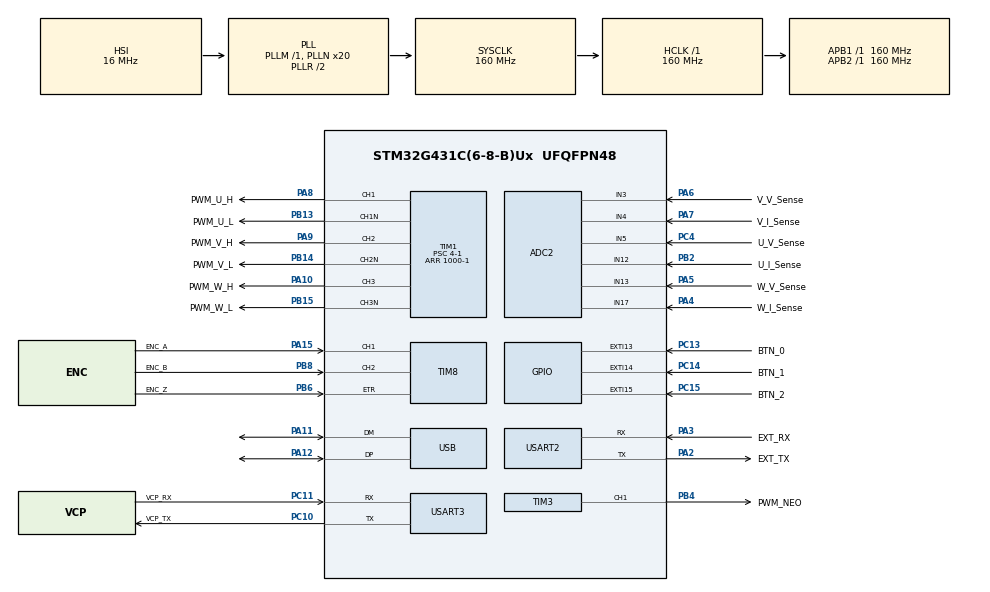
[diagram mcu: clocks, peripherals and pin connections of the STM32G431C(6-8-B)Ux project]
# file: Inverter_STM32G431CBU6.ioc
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ADC2.Channel-0\#ChannelRegularConversion=ADC_CHANNEL_5
ADC2.Channel-1\#ChannelRegularConversion=ADC_CHANNEL_3
ADC2.Channel-2\#ChannelRegularConversion=ADC_CHANNEL_13
ADC2.Channel-3\#ChannelRegularConversion=ADC_CHANNEL_12
ADC2.Channel-4\#ChannelRegularConversion=ADC_CHANNEL_4
ADC2.Channel-5\#ChannelRegularConversion=ADC_CHANNEL_17
ADC2.DMAContinuousRequests=ENABLE
ADC2.ExternalTrigConv=ADC_EXTERNALTRIG_T1_TRGO
ADC2.NbrOfConversion=6
ADC2.NbrOfConversionFlag=1
ADC2.OffsetNumber-0\#ChannelRegularConversion=ADC_OFFSET_NONE
ADC2.OffsetNumber-1\#ChannelRegularConversion=ADC_OFFSET_NONE
ADC2.OffsetNumber-2\#ChannelRegularConversion=ADC_OFFSET_NONE
ADC2.OffsetNumber-3\#ChannelRegularConversion=ADC_OFFSET_NONE
ADC2.OffsetNumber-4\#ChannelRegularConversion=ADC_OFFSET_NONE
ADC2.OffsetNumber-5\#ChannelRegularConversion=ADC_OFFSET_NONE
ADC2.Rank-0\#ChannelRegularConversion=1
ADC2.Rank-1\#ChannelRegularConversion=2
ADC2.Rank-2\#ChannelRegularConversion=3
ADC2.Rank-3\#ChannelRegularConversion=4
ADC2.Rank-4\#ChannelRegularConversion=5
ADC2.Rank-5\#ChannelRegularConversion=6
ADC2.SamplingTime-0\#ChannelRegularConversion=ADC_SAMPLETIME_12CYCLES_5
ADC2.SamplingTime-1\#ChannelRegularConversion=ADC_SAMPLETIME_12CYCLES_5
ADC2.SamplingTime-2\#ChannelRegularConversion=ADC_SAMPLETIME_12CYCLES_5
ADC2.SamplingTime-3\#ChannelRegularConversion=ADC_SAMPLETIME_12CYCLES_5
ADC2.SamplingTime-4\#ChannelRegularConversion=ADC_SAMPLETIME_12CYCLES_5
ADC2.SamplingTime-5\#ChannelRegularConversion=ADC_SAMPLETIME_12CYCLES_5
Dma.ADC2.1.Direction=DMA_PERIPH_TO_MEMORY
Dma.ADC2.1.EventEnable=DISABLE
Dma.ADC2.1.Instance=DMA1_Channel2
Dma.ADC2.1.MemDataAlignment=DMA_MDATAALIGN_HALFWORD
Dma.ADC2.1.MemInc=DMA_MINC_ENABLE
Dma.ADC2.1.Mode=DMA_CIRCULAR
Dma.ADC2.1.PeriphDataAlignment=DMA_PDATAALIGN_HALFWORD
Dma.ADC2.1.PeriphInc=DMA_PINC_DISABLE
Dma.ADC2.1.Polarity=HAL_DMAMUX_REQ_GEN_RISING
Dma.ADC2.1.Priority=DMA_PRIORITY_LOW
Dma.ADC2.1.RequestNumber=1
Dma.ADC2.1.SignalID=NONE
Dma.ADC2.1.SyncEnable=DISABLE
Dma.ADC2.1.SyncPolarity=HAL_DMAMUX_SYNC_NO_EVENT
Dma.ADC2.1.SyncRequestNumber=1
Dma.ADC2.1.SyncSignalID=NONE
Dma.Request0=TIM3_CH1
Dma.Request1=ADC2
Dma.TIM3_CH1.0.Direction=DMA_MEMORY_TO_PERIPH
Dma.TIM3_CH1.0.EventEnable=DISABLE
Dma.TIM3_CH1.0.Instance=DMA1_Channel1
Dma.TIM3_CH1.0.MemDataAlignment=DMA_MDATAALIGN_HALFWORD
Dma.TIM3_CH1.0.MemInc=DMA_MINC_ENABLE
Dma.TIM3_CH1.0.Mode=DMA_NORMAL
Dma.TIM3_CH1.0.PeriphDataAlignment=DMA_PDATAALIGN_HALFWORD
Dma.TIM3_CH1.0.PeriphInc=DMA_PINC_DISABLE
Dma.TIM3_CH1.0.Polarity=HAL_DMAMUX_REQ_GEN_RISING
Dma.TIM3_CH1.0.Priority=DMA_PRIORITY_LOW
Dma.TIM3_CH1.0.RequestNumber=1
Dma.TIM3_CH1.0.SignalID=NONE
Dma.TIM3_CH1.0.SyncEnable=DISABLE
Dma.TIM3_CH1.0.SyncPolarity=HAL_DMAMUX_SYNC_NO_EVENT
Dma.TIM3_CH1.0.SyncRequestNumber=1
Dma.TIM3_CH1.0.SyncSignalID=NONE
Mcu.Family=STM32G4
Mcu.Name=STM32G431C(6-8-B)Ux
Mcu.Package=UFQFPN48
NVIC.DMA1_Channel1_IRQn=true\:0\:0\:false\:false\:true\:false\:true\:true
NVIC.DMA1_Channel2_IRQn=true\:0\:0\:false\:false\:true\:false\:true\:true
NVIC.EXTI15_10_IRQn=true\:5\:0\:true\:false\:true\:true\:true\:true
NVIC.PriorityGroup=NVIC_PRIORITYGROUP_4
NVIC.TIM4_IRQn=true\:5\:0\:true\:false\:true\:true\:true\:true
NVIC.TIM6_DAC_IRQn=true\:15\:0\:false\:false\:true\:false\:true\:true
NVIC.TimeBase=TIM6_DAC_IRQn
NVIC.TimeBaseIP=TIM6
NVIC.USART2_IRQn=true\:0\:0\:false\:false\:true\:true\:true\:true
NVIC.USART3_IRQn=true\:5\:0\:true\:false\:true\:true\:true\:true
NVIC.USB_HP_IRQn=true\:0\:0\:false\:false\:true\:true\:true\:true
NVIC.USB_LP_IRQn=true\:0\:0\:false\:false\:true\:true\:true\:true
PA10.GPIO_Label=PWM_W_H
PA10.Signal=S_TIM1_CH3
PA11.Mode=Device
PA11.Signal=USB_DM
PA12.Mode=Device
PA12.Signal=USB_DP
PA13.Mode=Trace_Asynchronous_SW
PA13.Signal=SYS_JTMS-SWDIO
PA14.Mode=Trace_Asynchronous_SW
PA14.Signal=SYS_JTCK-SWCLK
PA15.GPIO_Label=ENC_A
PA15.Signal=S_TIM8_CH1
PA2.GPIO_Label=EXT_TX
PA2.Mode=Asynchronous
PA2.Signal=USART2_TX
PA3.GPIO_Label=EXT_RX
PA3.Mode=Asynchronous
PA3.Signal=USART2_RX
PA4.GPIO_Label=W_I_Sense
PA4.Mode=IN17-Single-Ended
PA4.Signal=ADC2_IN17
PA5.GPIO_Label=W_V_Sense
PA5.Mode=IN13-Single-Ended
PA5.Signal=ADC2_IN13
PA6.GPIO_Label=V_V_Sense
PA6.Mode=IN3-Single-Ended
PA6.Signal=ADC2_IN3
PA7.GPIO_Label=V_I_Sense
PA7.Mode=IN4-Single-Ended
PA7.Signal=ADC2_IN4
PA8.GPIO_Label=PWM_U_H
PA8.Signal=S_TIM1_CH1
PA9.GPIO_Label=PWM_V_H
PA9.Signal=S_TIM1_CH2
PB13.GPIO_Label=PWM_U_L
PB13.Mode=PWM Generation1 CH1 CH1N
PB13.Signal=TIM1_CH1N
PB14.GPIO_Label=PWM_V_L
PB14.Mode=PWM Generation2 CH2 CH2N
PB14.Signal=TIM1_CH2N
PB15.GPIO_Label=PWM_W_L
PB15.Mode=PWM Generation3 CH3 CH3N
PB15.Signal=TIM1_CH3N
PB2.GPIO_Label=U_I_Sense
PB2.Mode=IN12-Single-Ended
PB2.Signal=ADC2_IN12
PB3.Mode=Trace_Asynchronous_SW
PB3.Signal=SYS_JTDO-SWO
PB4.GPIO_Label=PWM_NEO
PB4.Signal=S_TIM3_CH1
PB6.GPIO_Label=ENC_Z
PB6.Signal=S_TIM8_ETR
PB8-BOOT0.GPIO_Label=ENC_B
PB8-BOOT0.Signal=S_TIM8_CH2
PC10.GPIO_Label=VCP_TX
PC10.Mode=Asynchronous
PC10.Signal=USART3_TX
PC11.GPIO_Label=VCP_RX
PC11.Mode=Asynchronous
PC11.Signal=USART3_RX
PC13.GPIO_Label=BTN_0
PC13.Signal=GPXTI13
PC14-OSC32_IN.GPIO_Label=BTN_1
PC14-OSC32_IN.Signal=GPXTI14
PC15-OSC32_OUT.GPIO_Label=BTN_2
PC15-OSC32_OUT.Signal=GPXTI15
PC4.GPIO_Label=U_V_Sense
PC4.Mode=IN5-Single-Ended
PC4.Signal=ADC2_IN5
ProjectManager.HeapSize=0x200
ProjectManager.StackSize=0x400
ProjectManager.TargetToolchain=STM32CubeIDE
RCC.ADC12Freq_Value=160000000
RCC.AHBFreq_Value=160000000
RCC.APB1Freq_Value=160000000
RCC.APB1TimFreq_Value=160000000
RCC.APB2Freq_Value=160000000
RCC.APB2TimFreq_Value=160000000
RCC.CK48CLockSelection=RCC_USBCLKSOURCE_HSI48
RCC.CortexFreq_Value=160000000
RCC.EXTERNAL_CLOCK_VALUE=12288000
RCC.HCLKFreq_Value=160000000
RCC.HSE_VALUE=8000000
RCC.HSI48_VALUE=48000000
RCC.HSI_VALUE=16000000
RCC.LSE_VALUE=32768
RCC.PLLN=20
RCC.SYSCLKFreq_VALUE=160000000
RCC.SYSCLKSource=RCC_SYSCLKSOURCE_PLLCLK
RCC.USBFreq_Value=48000000
RCC.VCOOutputFreq_Value=320000000
SH.S_TIM1_CH1.0=TIM1_CH1,PWM Generation1 CH1 CH1N
SH.S_TIM1_CH2.0=TIM1_CH2,PWM Generation2 CH2 CH2N
SH.S_TIM1_CH3.0=TIM1_CH3,PWM Generation3 CH3 CH3N
SH.S_TIM3_CH1.0=TIM3_CH1,PWM Generation1 CH1
SH.S_TIM8_CH1.0=TIM8_CH1,Encoder_Interface_w_index
SH.S_TIM8_CH2.0=TIM8_CH2,Encoder_Interface_w_index
SH.S_TIM8_ETR.0=TIM8_ETR,Encoder_Interface_w_index
TIM1.AutoReloadPreload=TIM_AUTORELOAD_PRELOAD_ENABLE
TIM1.Channel-PWM\ Generation1\ CH1\ CH1N=TIM_CHANNEL_1
TIM1.Channel-PWM\ Generation2\ CH2\ CH2N=TIM_CHANNEL_2
TIM1.Channel-PWM\ Generation3\ CH3\ CH3N=TIM_CHANNEL_3
TIM1.DeadTime=50
TIM1.PeriodNoDither=1000-1
TIM1.Prescaler=4-1
TIM1.PulseNoDither_1=500-1
TIM1.PulseNoDither_2=500-1
TIM1.TIM_MasterOutputTrigger=TIM_TRGO_UPDATE
TIM3.Channel-PWM\ Generation1\ CH1=TIM_CHANNEL_1
TIM3.PeriodNoDither=20-1
TIM3.Prescaler=10-1
TIM4.PeriodNoDither=10000-1
TIM4.Prescaler=160-1
TIM8.CounterMode=TIM_COUNTERMODE_UP
TIM8.EncoderMode=TIM_ENCODERMODE_TI1
USART2.VirtualMode-Asynchronous=VM_ASYNC
USART3.VirtualMode-Asynchronous=VM_ASYNC
VP_SYS_VS_DBSignals.Mode=DisableDeadBatterySignals
VP_SYS_VS_tim6.Mode=TIM6
VP_TIM1_VS_ClockSourceINT.Mode=Internal
VP_TIM3_VS_ClockSourceINT.Mode=Internal
VP_TIM4_VS_ClockSourceINT.Mode=Internal
board=custom

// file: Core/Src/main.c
/* USER CODE BEGIN Header */
/**
 ******************************************************************************
 * @file           : main.c
 * @brief          : Main program body
 ******************************************************************************
 * @attention
 *
 * Copyright (c) 2026 STMicroelectronics.
 * All rights reserved.
 *
 * This software is licensed under terms that can be found in the LICENSE file
 * in the root directory of this software component.
 * If no LICENSE file comes with this software, it is provided AS-IS.
 *
 ******************************************************************************
 */
/* USER CODE END Header */
#include "main.h"
#include "adc.h"
#include "dma.h"
#include "tim.h"
#include "usart.h"
#include "usb.h"
#include "gpio.h"

/* USER CODE BEGIN Includes */
#include "app.h"

/* USER CODE END Includes */

/* USER CODE BEGIN PTD */
#define PUTCHAR_PROTOTYPE int __io_putchar(int ch)
PUTCHAR_PROTOTYPE
{
	/* Place your implementation of fputc here */
	/* e.g. write a character to the USART1 and Loop until the end of transmission */
	HAL_UART_Transmit(&huart3, (uint8_t *)&ch, 1, 0xFFFF);

	return ch;
}
/* USER CODE END PTD */

/* USER CODE BEGIN PV */
uint8_t tick_10ms = 0;
/* USER CODE END PV */

void SystemClock_Config(void);

int main(void)
{

  /* MCU Configuration--------------------------------------------------------*/

  /* Reset of all peripherals, Initializes the Flash interface and the Systick. */
  HAL_Init();

  /* Configure the system clock */
  SystemClock_Config();

  /* Initialize all configured peripherals */
  MX_GPIO_Init();
  MX_DMA_Init();
  MX_ADC2_Init();
  MX_TIM1_Init();
  MX_TIM3_Init();
  MX_TIM8_Init();
  MX_USART2_UART_Init();
  MX_USART3_UART_Init();
  MX_USB_PCD_Init();
  MX_TIM4_Init();
  /* USER CODE BEGIN 2 */

	init_device();
  /* USER CODE END 2 */

  /* Infinite loop */
  /* USER CODE BEGIN WHILE */
	while (1)
	{
		if(tick_10ms){
			loop();
			tick_10ms = 0;
		}

		HAL_Delay(1);
    /* USER CODE END WHILE */

	}
}

void SystemClock_Config(void)
{
  RCC_OscInitTypeDef RCC_OscInitStruct = {0};
  RCC_ClkInitTypeDef RCC_ClkInitStruct = {0};

  /** Configure the main internal regulator output voltage
  */
  HAL_PWREx_ControlVoltageScaling(PWR_REGULATOR_VOLTAGE_SCALE1_BOOST);

  /** Initializes the RCC Oscillators according to the specified parameters
  * in the RCC_OscInitTypeDef structure.
  */
  RCC_OscInitStruct.OscillatorType = RCC_OSCILLATORTYPE_HSI|RCC_OSCILLATORTYPE_HSI48;
  RCC_OscInitStruct.HSIState = RCC_HSI_ON;
  RCC_OscInitStruct.HSICalibrationValue = RCC_HSICALIBRATION_DEFAULT;
  RCC_OscInitStruct.HSI48State = RCC_HSI48_ON;
  RCC_OscInitStruct.PLL.PLLState = RCC_PLL_ON;
  RCC_OscInitStruct.PLL.PLLSource = RCC_PLLSOURCE_HSI;
  RCC_OscInitStruct.PLL.PLLM = RCC_PLLM_DIV1;
  RCC_OscInitStruct.PLL.PLLN = 20;
  RCC_OscInitStruct.PLL.PLLP = RCC_PLLP_DIV2;
  RCC_OscInitStruct.PLL.PLLQ = RCC_PLLQ_DIV2;
  RCC_OscInitStruct.PLL.PLLR = RCC_PLLR_DIV2;
  if (HAL_RCC_OscConfig(&RCC_OscInitStruct) != HAL_OK)
  {
    Error_Handler();
  }

  /** Initializes the CPU, AHB and APB buses clocks
  */
  RCC_ClkInitStruct.ClockType = RCC_CLOCKTYPE_HCLK|RCC_CLOCKTYPE_SYSCLK
                              |RCC_CLOCKTYPE_PCLK1|RCC_CLOCKTYPE_PCLK2;
  RCC_ClkInitStruct.SYSCLKSource = RCC_SYSCLKSOURCE_PLLCLK;
  RCC_ClkInitStruct.AHBCLKDivider = RCC_SYSCLK_DIV1;
  RCC_ClkInitStruct.APB1CLKDivider = RCC_HCLK_DIV1;
  RCC_ClkInitStruct.APB2CLKDivider = RCC_HCLK_DIV1;

  if (HAL_RCC_ClockConfig(&RCC_ClkInitStruct, FLASH_LATENCY_4) != HAL_OK)
  {
    Error_Handler();
  }
}

void HAL_TIM_PeriodElapsedCallback(TIM_HandleTypeDef *htim)
{
  /* USER CODE BEGIN Callback 0 */
	if (htim->Instance == TIM4){
		tick_10ms = 1;
	}
  /* USER CODE END Callback 0 */
  if (htim->Instance == TIM6)
  {
    HAL_IncTick();
  }
}

void Error_Handler(void)
{
	__disable_irq();
	while (1)
	{
	}
}
